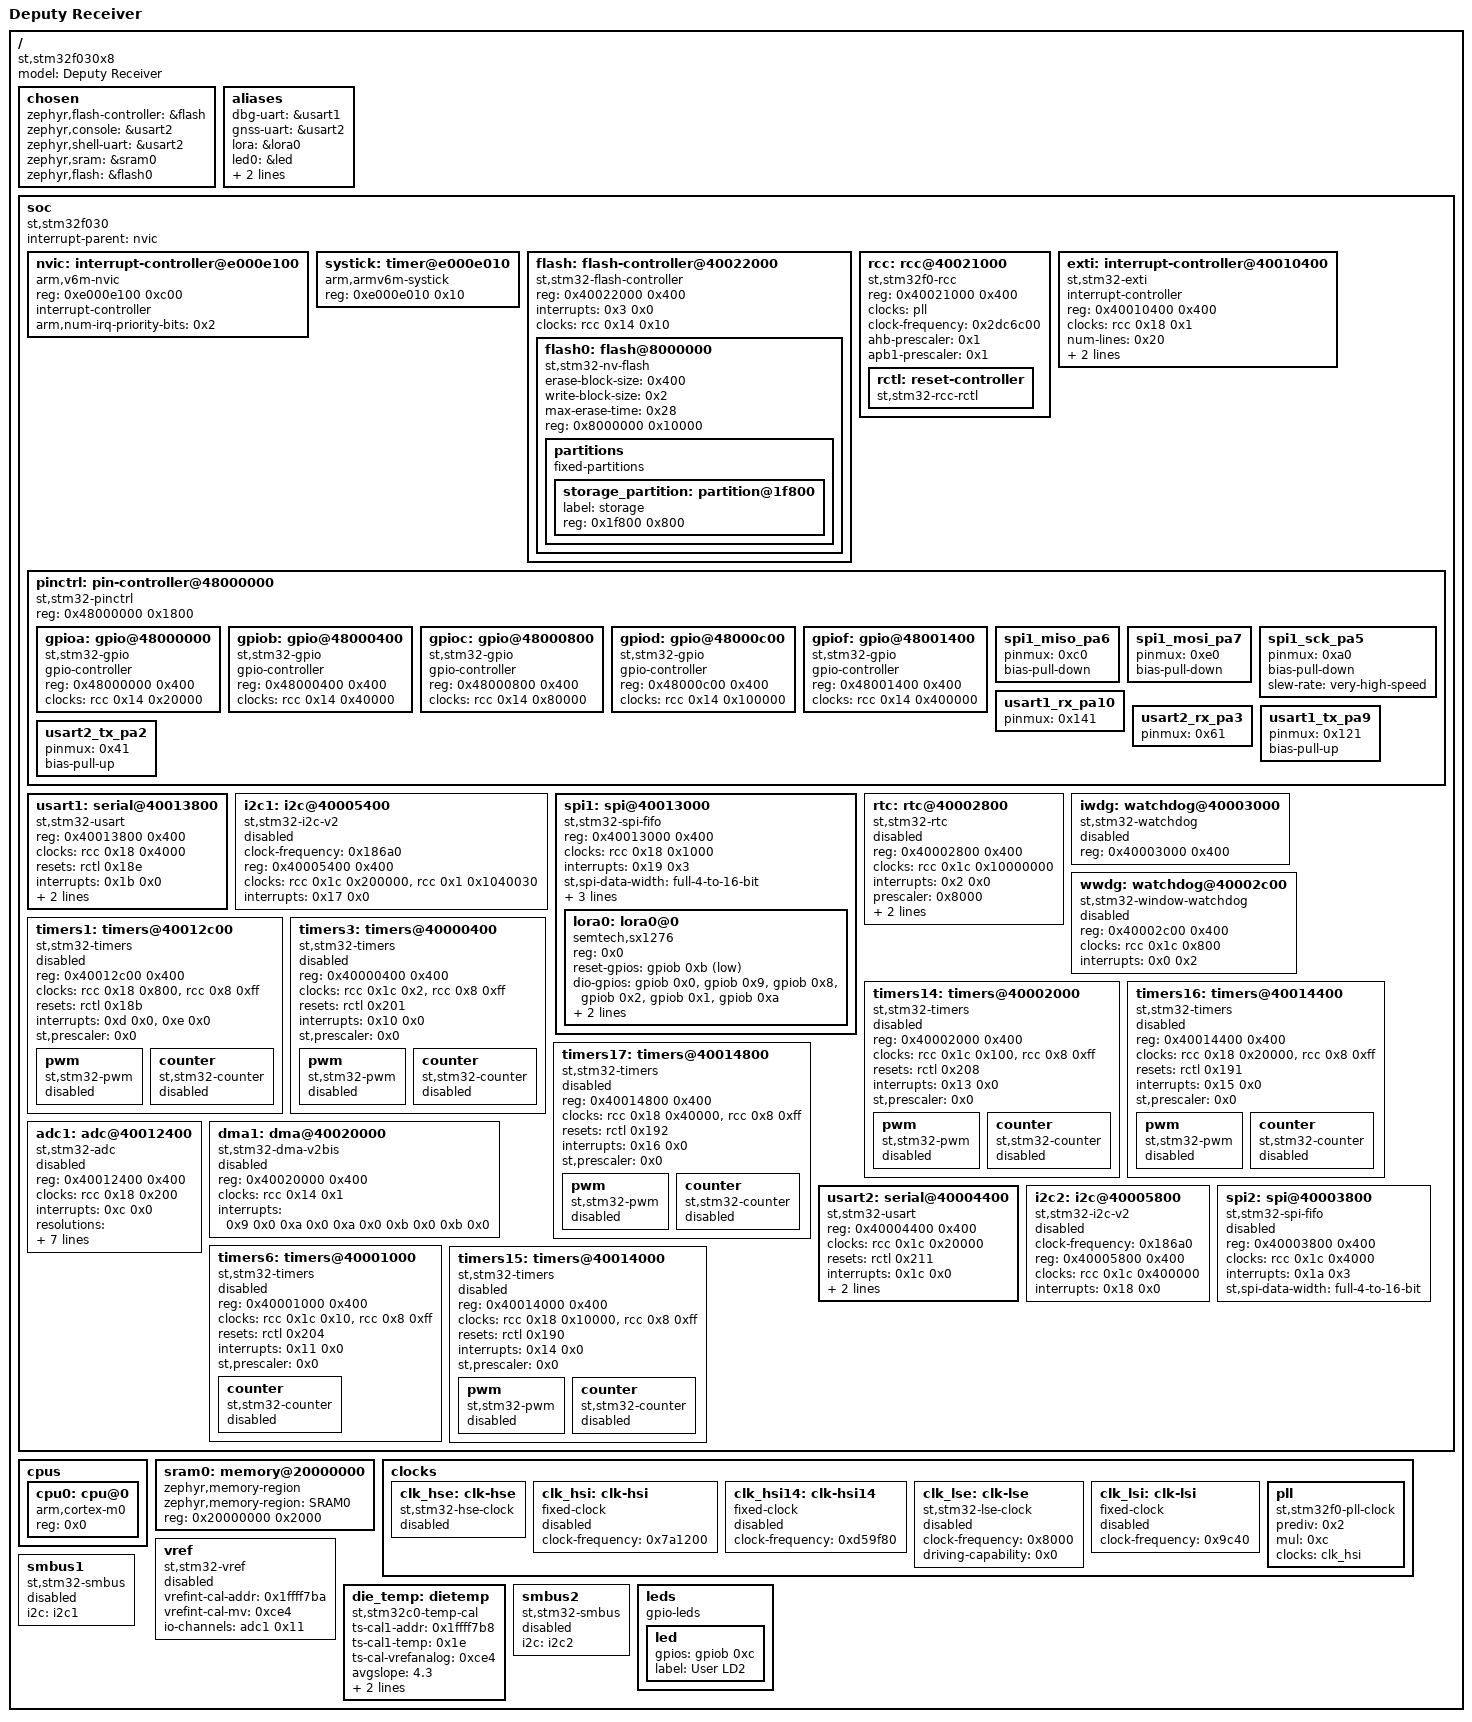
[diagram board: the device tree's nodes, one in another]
/dts-v1/;

/* node '/' defined in zephyr/dts/common/skeleton.dtsi:9 */
/ {
	#address-cells = < 0x1 >;      /* in zephyr/dts/common/skeleton.dtsi:10 */
	#size-cells = < 0x1 >;         /* in zephyr/dts/common/skeleton.dtsi:11 */
	model = "Deputy Receiver";     /* in Outlaw-GPS-Tracker-Firmware/boards/deputy/deputy.dts:13 */
	compatible = "st,stm32f030x8"; /* in Outlaw-GPS-Tracker-Firmware/boards/deputy/deputy.dts:14 */

	/* node '/chosen' defined in zephyr/dts/common/skeleton.dtsi:13 */
	chosen {
		zephyr,flash-controller = &flash; /* in zephyr/dts/arm/st/f0/stm32f0.dtsi:24 */
		zephyr,console = &usart2;         /* in Outlaw-GPS-Tracker-Firmware/boards/deputy/deputy.dts:17 */
		zephyr,shell-uart = &usart2;      /* in Outlaw-GPS-Tracker-Firmware/boards/deputy/deputy.dts:18 */
		zephyr,sram = &sram0;             /* in Outlaw-GPS-Tracker-Firmware/boards/deputy/deputy.dts:19 */
		zephyr,flash = &flash0;           /* in Outlaw-GPS-Tracker-Firmware/boards/deputy/deputy.dts:20 */
	};

	/* node '/aliases' defined in zephyr/dts/common/skeleton.dtsi:15 */
	aliases {
		dbg-uart = &usart1;    /* in Outlaw-GPS-Tracker-Firmware/boards/deputy/deputy.dts:32 */
		gnss-uart = &usart2;   /* in Outlaw-GPS-Tracker-Firmware/boards/deputy/deputy.dts:33 */
		lora = &lora0;         /* in Outlaw-GPS-Tracker-Firmware/boards/deputy/deputy.dts:34 */
		led0 = &led;           /* in Outlaw-GPS-Tracker-Firmware/boards/deputy/deputy.dts:35 */
		watchdog0 = &iwdg;     /* in Outlaw-GPS-Tracker-Firmware/boards/deputy/deputy.dts:36 */
		die-temp0 = &die_temp; /* in Outlaw-GPS-Tracker-Firmware/boards/deputy/deputy.dts:37 */
	};

	/* node '/soc' defined in zephyr/dts/arm/armv6-m.dtsi:6 */
	soc {
		#address-cells = < 0x1 >;     /* in zephyr/dts/arm/armv6-m.dtsi:7 */
		#size-cells = < 0x1 >;        /* in zephyr/dts/arm/armv6-m.dtsi:8 */
		interrupt-parent = < &nvic >; /* in zephyr/dts/arm/armv6-m.dtsi:10 */
		ranges;                       /* in zephyr/dts/arm/armv6-m.dtsi:11 */
		compatible = "st,stm32f030",
		             "st,stm32f0",
		             "simple-bus";    /* in zephyr/dts/arm/st/f0/stm32f030.dtsi:11 */

		/* node '/soc/interrupt-controller@e000e100' defined in zephyr/dts/arm/armv6-m.dtsi:13 */
		nvic: interrupt-controller@e000e100 {
			#address-cells = < 0x1 >;            /* in zephyr/dts/arm/armv6-m.dtsi:14 */
			compatible = "arm,v6m-nvic";         /* in zephyr/dts/arm/armv6-m.dtsi:15 */
			reg = < 0xe000e100 0xc00 >;          /* in zephyr/dts/arm/armv6-m.dtsi:16 */
			interrupt-controller;                /* in zephyr/dts/arm/armv6-m.dtsi:17 */
			#interrupt-cells = < 0x2 >;          /* in zephyr/dts/arm/armv6-m.dtsi:18 */
			arm,num-irq-priority-bits = < 0x2 >; /* in zephyr/dts/arm/st/f0/stm32f0.dtsi:399 */
			phandle = < 0x1 >;                   /* in zephyr/dts/arm/armv6-m.dtsi:10 */
		};

		/* node '/soc/timer@e000e010' defined in zephyr/dts/arm/armv6-m.dtsi:21 */
		systick: timer@e000e010 {
			compatible = "arm,armv6m-systick"; /* in zephyr/dts/arm/armv6-m.dtsi:22 */
			reg = < 0xe000e010 0x10 >;         /* in zephyr/dts/arm/armv6-m.dtsi:23 */
		};

		/* node '/soc/flash-controller@40022000' defined in zephyr/dts/arm/st/f0/stm32f0.dtsi:87 */
		flash: flash-controller@40022000 {
			compatible = "st,stm32-flash-controller",
			             "st,stm32f1-flash-controller"; /* in zephyr/dts/arm/st/f0/stm32f0.dtsi:88 */
			reg = < 0x40022000 0x400 >;                 /* in zephyr/dts/arm/st/f0/stm32f0.dtsi:89 */
			interrupts = < 0x3 0x0 >;                   /* in zephyr/dts/arm/st/f0/stm32f0.dtsi:90 */
			clocks = < &rcc 0x14 0x10 >;                /* in zephyr/dts/arm/st/f0/stm32f0.dtsi:91 */
			#address-cells = < 0x1 >;                   /* in zephyr/dts/arm/st/f0/stm32f0.dtsi:93 */
			#size-cells = < 0x1 >;                      /* in zephyr/dts/arm/st/f0/stm32f0.dtsi:94 */

			/* node '/soc/flash-controller@40022000/flash@8000000' defined in zephyr/dts/arm/st/f0/stm32f0.dtsi:96 */
			flash0: flash@8000000 {
				compatible = "st,stm32-nv-flash",
				             "soc-nv-flash";      /* in zephyr/dts/arm/st/f0/stm32f0.dtsi:97 */
				erase-block-size = < 0x400 >;     /* in zephyr/dts/arm/st/f0/stm32f0.dtsi:98 */
				write-block-size = < 0x2 >;       /* in zephyr/dts/arm/st/f0/stm32f0.dtsi:99 */
				max-erase-time = < 0x28 >;        /* in zephyr/dts/arm/st/f0/stm32f0.dtsi:101 */
				reg = < 0x8000000 0x10000 >;      /* in zephyr/dts/arm/st/f0/stm32f030X8.dtsi:16 */

				/* node '/soc/flash-controller@40022000/flash@8000000/partitions' defined in Outlaw-GPS-Tracker-Firmware/boards/deputy/deputy.dts:99 */
				partitions {
					compatible = "fixed-partitions"; /* in Outlaw-GPS-Tracker-Firmware/boards/deputy/deputy.dts:100 */
					#address-cells = < 0x1 >;        /* in Outlaw-GPS-Tracker-Firmware/boards/deputy/deputy.dts:101 */
					#size-cells = < 0x1 >;           /* in Outlaw-GPS-Tracker-Firmware/boards/deputy/deputy.dts:102 */

					/* node '/soc/flash-controller@40022000/flash@8000000/partitions/partition@1f800' defined in Outlaw-GPS-Tracker-Firmware/boards/deputy/deputy.dts:105 */
					storage_partition: partition@1f800 {
						label = "storage";       /* in Outlaw-GPS-Tracker-Firmware/boards/deputy/deputy.dts:106 */
						reg = < 0x1f800 0x800 >; /* in Outlaw-GPS-Tracker-Firmware/boards/deputy/deputy.dts:107 */
					};
				};
			};
		};

		/* node '/soc/rcc@40021000' defined in zephyr/dts/arm/st/f0/stm32f0.dtsi:105 */
		rcc: rcc@40021000 {
			compatible = "st,stm32f0-rcc";   /* in zephyr/dts/arm/st/f0/stm32f0.dtsi:106 */
			#clock-cells = < 0x2 >;          /* in zephyr/dts/arm/st/f0/stm32f0.dtsi:107 */
			reg = < 0x40021000 0x400 >;      /* in zephyr/dts/arm/st/f0/stm32f0.dtsi:108 */
			clocks = < &pll >;               /* in Outlaw-GPS-Tracker-Firmware/boards/deputy/deputy.dts:49 */
			clock-frequency = < 0x2dc6c00 >; /* in Outlaw-GPS-Tracker-Firmware/boards/deputy/deputy.dts:50 */
			ahb-prescaler = < 0x1 >;         /* in Outlaw-GPS-Tracker-Firmware/boards/deputy/deputy.dts:51 */
			apb1-prescaler = < 0x1 >;        /* in Outlaw-GPS-Tracker-Firmware/boards/deputy/deputy.dts:52 */
			phandle = < 0x2 >;               /* in zephyr/dts/arm/st/f0/stm32f0.dtsi:91 */

			/* node '/soc/rcc@40021000/reset-controller' defined in zephyr/dts/arm/st/f0/stm32f0.dtsi:110 */
			rctl: reset-controller {
				compatible = "st,stm32-rcc-rctl"; /* in zephyr/dts/arm/st/f0/stm32f0.dtsi:111 */
				#reset-cells = < 0x1 >;           /* in zephyr/dts/arm/st/f0/stm32f0.dtsi:112 */
				phandle = < 0x4 >;                /* in zephyr/dts/arm/st/f0/stm32f0.dtsi:180 */
			};
		};

		/* node '/soc/interrupt-controller@40010400' defined in zephyr/dts/arm/st/f0/stm32f0.dtsi:116 */
		exti: interrupt-controller@40010400 {
			compatible = "st,stm32-exti"; /* in zephyr/dts/arm/st/f0/stm32f0.dtsi:117 */
			interrupt-controller;         /* in zephyr/dts/arm/st/f0/stm32f0.dtsi:118 */
			#interrupt-cells = < 0x1 >;   /* in zephyr/dts/arm/st/f0/stm32f0.dtsi:119 */
			#address-cells = < 0x0 >;     /* in zephyr/dts/arm/st/f0/stm32f0.dtsi:120 */
			reg = < 0x40010400 0x400 >;   /* in zephyr/dts/arm/st/f0/stm32f0.dtsi:121 */
			clocks = < &rcc 0x18 0x1 >;   /* in zephyr/dts/arm/st/f0/stm32f0.dtsi:122 */
			num-lines = < 0x20 >;         /* in zephyr/dts/arm/st/f0/stm32f0.dtsi:123 */
			interrupts = < 0x5 0x0 >,
			             < 0x6 0x0 >,
			             < 0x7 0x0 >;     /* in zephyr/dts/arm/st/f0/stm32f0.dtsi:124 */
			interrupt-names = "line0-1",
			                  "line2-3",
			                  "line4-15"; /* in zephyr/dts/arm/st/f0/stm32f0.dtsi:125 */
			line-ranges = < 0x0 0x2 >,
			              < 0x2 0x2 >,
			              < 0x4 0xc >;    /* in zephyr/dts/arm/st/f0/stm32f0.dtsi:126 */
		};

		/* node '/soc/pin-controller@48000000' defined in zephyr/dts/arm/st/f0/stm32f0.dtsi:129 */
		pinctrl: pin-controller@48000000 {
			compatible = "st,stm32-pinctrl"; /* in zephyr/dts/arm/st/f0/stm32f0.dtsi:130 */
			#address-cells = < 0x1 >;        /* in zephyr/dts/arm/st/f0/stm32f0.dtsi:131 */
			#size-cells = < 0x1 >;           /* in zephyr/dts/arm/st/f0/stm32f0.dtsi:132 */
			reg = < 0x48000000 0x1800 >;     /* in zephyr/dts/arm/st/f0/stm32f0.dtsi:133 */

			/* node '/soc/pin-controller@48000000/gpio@48000000' defined in zephyr/dts/arm/st/f0/stm32f0.dtsi:135 */
			gpioa: gpio@48000000 {
				compatible = "st,stm32-gpio";   /* in zephyr/dts/arm/st/f0/stm32f0.dtsi:136 */
				gpio-controller;                /* in zephyr/dts/arm/st/f0/stm32f0.dtsi:137 */
				#gpio-cells = < 0x2 >;          /* in zephyr/dts/arm/st/f0/stm32f0.dtsi:138 */
				reg = < 0x48000000 0x400 >;     /* in zephyr/dts/arm/st/f0/stm32f0.dtsi:139 */
				clocks = < &rcc 0x14 0x20000 >; /* in zephyr/dts/arm/st/f0/stm32f0.dtsi:140 */
				phandle = < 0xa >;              /* in Outlaw-GPS-Tracker-Firmware/boards/deputy/deputy.dts:75 */
			};

			/* node '/soc/pin-controller@48000000/gpio@48000400' defined in zephyr/dts/arm/st/f0/stm32f0.dtsi:143 */
			gpiob: gpio@48000400 {
				compatible = "st,stm32-gpio";   /* in zephyr/dts/arm/st/f0/stm32f0.dtsi:144 */
				gpio-controller;                /* in zephyr/dts/arm/st/f0/stm32f0.dtsi:145 */
				#gpio-cells = < 0x2 >;          /* in zephyr/dts/arm/st/f0/stm32f0.dtsi:146 */
				reg = < 0x48000400 0x400 >;     /* in zephyr/dts/arm/st/f0/stm32f0.dtsi:147 */
				clocks = < &rcc 0x14 0x40000 >; /* in zephyr/dts/arm/st/f0/stm32f0.dtsi:148 */
				phandle = < 0xb >;              /* in Outlaw-GPS-Tracker-Firmware/boards/deputy/deputy.dts:81 */
			};

			/* node '/soc/pin-controller@48000000/gpio@48000800' defined in zephyr/dts/arm/st/f0/stm32f0.dtsi:151 */
			gpioc: gpio@48000800 {
				compatible = "st,stm32-gpio";   /* in zephyr/dts/arm/st/f0/stm32f0.dtsi:152 */
				gpio-controller;                /* in zephyr/dts/arm/st/f0/stm32f0.dtsi:153 */
				#gpio-cells = < 0x2 >;          /* in zephyr/dts/arm/st/f0/stm32f0.dtsi:154 */
				reg = < 0x48000800 0x400 >;     /* in zephyr/dts/arm/st/f0/stm32f0.dtsi:155 */
				clocks = < &rcc 0x14 0x80000 >; /* in zephyr/dts/arm/st/f0/stm32f0.dtsi:156 */
			};

			/* node '/soc/pin-controller@48000000/gpio@48000c00' defined in zephyr/dts/arm/st/f0/stm32f0.dtsi:159 */
			gpiod: gpio@48000c00 {
				compatible = "st,stm32-gpio";    /* in zephyr/dts/arm/st/f0/stm32f0.dtsi:160 */
				gpio-controller;                 /* in zephyr/dts/arm/st/f0/stm32f0.dtsi:161 */
				#gpio-cells = < 0x2 >;           /* in zephyr/dts/arm/st/f0/stm32f0.dtsi:162 */
				reg = < 0x48000c00 0x400 >;      /* in zephyr/dts/arm/st/f0/stm32f0.dtsi:163 */
				clocks = < &rcc 0x14 0x100000 >; /* in zephyr/dts/arm/st/f0/stm32f0.dtsi:164 */
			};

			/* node '/soc/pin-controller@48000000/gpio@48001400' defined in zephyr/dts/arm/st/f0/stm32f0.dtsi:167 */
			gpiof: gpio@48001400 {
				compatible = "st,stm32-gpio";    /* in zephyr/dts/arm/st/f0/stm32f0.dtsi:168 */
				gpio-controller;                 /* in zephyr/dts/arm/st/f0/stm32f0.dtsi:169 */
				#gpio-cells = < 0x2 >;           /* in zephyr/dts/arm/st/f0/stm32f0.dtsi:170 */
				reg = < 0x48001400 0x400 >;      /* in zephyr/dts/arm/st/f0/stm32f0.dtsi:171 */
				clocks = < &rcc 0x14 0x400000 >; /* in zephyr/dts/arm/st/f0/stm32f0.dtsi:172 */
			};

			/* node '/soc/pin-controller@48000000/spi1_miso_pa6' defined in modules/hal/stm32/dts/st/f0/stm32f030c8tx-pinctrl.dtsi:291 */
			spi1_miso_pa6: spi1_miso_pa6 {
				pinmux = < 0xc0 >; /* in modules/hal/stm32/dts/st/f0/stm32f030c8tx-pinctrl.dtsi:292 */
				bias-pull-down;    /* in modules/hal/stm32/dts/st/f0/stm32f030c8tx-pinctrl.dtsi:293 */
				phandle = < 0x8 >; /* in Outlaw-GPS-Tracker-Firmware/boards/deputy/deputy.dts:73 */
			};

			/* node '/soc/pin-controller@48000000/spi1_mosi_pa7' defined in modules/hal/stm32/dts/st/f0/stm32f030c8tx-pinctrl.dtsi:308 */
			spi1_mosi_pa7: spi1_mosi_pa7 {
				pinmux = < 0xe0 >; /* in modules/hal/stm32/dts/st/f0/stm32f030c8tx-pinctrl.dtsi:309 */
				bias-pull-down;    /* in modules/hal/stm32/dts/st/f0/stm32f030c8tx-pinctrl.dtsi:310 */
				phandle = < 0x9 >; /* in Outlaw-GPS-Tracker-Firmware/boards/deputy/deputy.dts:73 */
			};

			/* node '/soc/pin-controller@48000000/spi1_sck_pa5' defined in modules/hal/stm32/dts/st/f0/stm32f030c8tx-pinctrl.dtsi:342 */
			spi1_sck_pa5: spi1_sck_pa5 {
				pinmux = < 0xa0 >;             /* in modules/hal/stm32/dts/st/f0/stm32f030c8tx-pinctrl.dtsi:343 */
				bias-pull-down;                /* in modules/hal/stm32/dts/st/f0/stm32f030c8tx-pinctrl.dtsi:344 */
				slew-rate = "very-high-speed"; /* in modules/hal/stm32/dts/st/f0/stm32f030c8tx-pinctrl.dtsi:345 */
				phandle = < 0x7 >;             /* in Outlaw-GPS-Tracker-Firmware/boards/deputy/deputy.dts:73 */
			};

			/* node '/soc/pin-controller@48000000/usart1_rx_pa10' defined in modules/hal/stm32/dts/st/f0/stm32f030c8tx-pinctrl.dtsi:542 */
			usart1_rx_pa10: usart1_rx_pa10 {
				pinmux = < 0x141 >; /* in modules/hal/stm32/dts/st/f0/stm32f030c8tx-pinctrl.dtsi:543 */
				phandle = < 0x6 >;  /* in Outlaw-GPS-Tracker-Firmware/boards/deputy/deputy.dts:58 */
			};

			/* node '/soc/pin-controller@48000000/usart2_rx_pa3' defined in modules/hal/stm32/dts/st/f0/stm32f030c8tx-pinctrl.dtsi:550 */
			usart2_rx_pa3: usart2_rx_pa3 {
				pinmux = < 0x61 >; /* in modules/hal/stm32/dts/st/f0/stm32f030c8tx-pinctrl.dtsi:551 */
				phandle = < 0xd >; /* in Outlaw-GPS-Tracker-Firmware/boards/deputy/deputy.dts:66 */
			};

			/* node '/soc/pin-controller@48000000/usart1_tx_pa9' defined in modules/hal/stm32/dts/st/f0/stm32f030c8tx-pinctrl.dtsi:560 */
			usart1_tx_pa9: usart1_tx_pa9 {
				pinmux = < 0x121 >; /* in modules/hal/stm32/dts/st/f0/stm32f030c8tx-pinctrl.dtsi:561 */
				bias-pull-up;       /* in modules/hal/stm32/dts/st/f0/stm32f030c8tx-pinctrl.dtsi:562 */
				phandle = < 0x5 >;  /* in Outlaw-GPS-Tracker-Firmware/boards/deputy/deputy.dts:58 */
			};

			/* node '/soc/pin-controller@48000000/usart2_tx_pa2' defined in modules/hal/stm32/dts/st/f0/stm32f030c8tx-pinctrl.dtsi:570 */
			usart2_tx_pa2: usart2_tx_pa2 {
				pinmux = < 0x41 >; /* in modules/hal/stm32/dts/st/f0/stm32f030c8tx-pinctrl.dtsi:571 */
				bias-pull-up;      /* in modules/hal/stm32/dts/st/f0/stm32f030c8tx-pinctrl.dtsi:572 */
				phandle = < 0xc >; /* in Outlaw-GPS-Tracker-Firmware/boards/deputy/deputy.dts:66 */
			};
		};

		/* node '/soc/serial@40013800' defined in zephyr/dts/arm/st/f0/stm32f0.dtsi:176 */
		usart1: serial@40013800 {
			compatible = "st,stm32-usart",
			             "st,stm32-uart";                   /* in zephyr/dts/arm/st/f0/stm32f0.dtsi:177 */
			reg = < 0x40013800 0x400 >;                     /* in zephyr/dts/arm/st/f0/stm32f0.dtsi:178 */
			clocks = < &rcc 0x18 0x4000 >;                  /* in zephyr/dts/arm/st/f0/stm32f0.dtsi:179 */
			resets = < &rctl 0x18e >;                       /* in zephyr/dts/arm/st/f0/stm32f0.dtsi:180 */
			interrupts = < 0x1b 0x0 >;                      /* in zephyr/dts/arm/st/f0/stm32f0.dtsi:181 */
			pinctrl-0 = < &usart1_tx_pa9 &usart1_rx_pa10 >; /* in Outlaw-GPS-Tracker-Firmware/boards/deputy/deputy.dts:58 */
			pinctrl-names = "default";                      /* in Outlaw-GPS-Tracker-Firmware/boards/deputy/deputy.dts:59 */
			current-speed = < 0x2580 >;                     /* in Outlaw-GPS-Tracker-Firmware/boards/deputy/deputy.dts:60 */
			status = "okay";                                /* in Outlaw-GPS-Tracker-Firmware/boards/deputy/deputy.dts:61 */
		};

		/* node '/soc/i2c@40005400' defined in zephyr/dts/arm/st/f0/stm32f0.dtsi:185 */
		i2c1: i2c@40005400 {
			compatible = "st,stm32-i2c-v2";  /* in zephyr/dts/arm/st/f0/stm32f0.dtsi:186 */
			clock-frequency = < 0x186a0 >;   /* in zephyr/dts/arm/st/f0/stm32f0.dtsi:187 */
			#address-cells = < 0x1 >;        /* in zephyr/dts/arm/st/f0/stm32f0.dtsi:188 */
			#size-cells = < 0x0 >;           /* in zephyr/dts/arm/st/f0/stm32f0.dtsi:189 */
			reg = < 0x40005400 0x400 >;      /* in zephyr/dts/arm/st/f0/stm32f0.dtsi:190 */
			clocks = < &rcc 0x1c 0x200000 >,
			         < &rcc 0x1 0x1040030 >; /* in zephyr/dts/arm/st/f0/stm32f0.dtsi:191 */
			interrupts = < 0x17 0x0 >;       /* in zephyr/dts/arm/st/f0/stm32f0.dtsi:196 */
			interrupt-names = "combined";    /* in zephyr/dts/arm/st/f0/stm32f0.dtsi:197 */
			status = "disabled";             /* in zephyr/dts/arm/st/f0/stm32f0.dtsi:198 */
			phandle = < 0x10 >;              /* in zephyr/dts/arm/st/f0/stm32f0.dtsi:393 */
		};

		/* node '/soc/spi@40013000' defined in zephyr/dts/arm/st/f0/stm32f0.dtsi:201 */
		spi1: spi@40013000 {
			compatible = "st,stm32-spi-fifo",
			             "st,stm32-spi";                                 /* in zephyr/dts/arm/st/f0/stm32f0.dtsi:202 */
			#address-cells = < 0x1 >;                                    /* in zephyr/dts/arm/st/f0/stm32f0.dtsi:203 */
			#size-cells = < 0x0 >;                                       /* in zephyr/dts/arm/st/f0/stm32f0.dtsi:204 */
			reg = < 0x40013000 0x400 >;                                  /* in zephyr/dts/arm/st/f0/stm32f0.dtsi:205 */
			clocks = < &rcc 0x18 0x1000 >;                               /* in zephyr/dts/arm/st/f0/stm32f0.dtsi:206 */
			interrupts = < 0x19 0x3 >;                                   /* in zephyr/dts/arm/st/f0/stm32f0.dtsi:207 */
			st,spi-data-width = "full-4-to-16-bit";                      /* in zephyr/dts/arm/st/f0/stm32f0.dtsi:208 */
			pinctrl-0 = < &spi1_sck_pa5 &spi1_miso_pa6 &spi1_mosi_pa7 >; /* in Outlaw-GPS-Tracker-Firmware/boards/deputy/deputy.dts:73 */
			pinctrl-names = "default";                                   /* in Outlaw-GPS-Tracker-Firmware/boards/deputy/deputy.dts:74 */
			cs-gpios = < &gpioa 0x4 0x11 >;                              /* in Outlaw-GPS-Tracker-Firmware/boards/deputy/deputy.dts:75 */
			status = "okay";                                             /* in Outlaw-GPS-Tracker-Firmware/boards/deputy/deputy.dts:76 */

			/* node '/soc/spi@40013000/lora0@0' defined in Outlaw-GPS-Tracker-Firmware/boards/deputy/deputy.dts:78 */
			lora0: lora0@0 {
				compatible = "semtech,sx1276";       /* in Outlaw-GPS-Tracker-Firmware/boards/deputy/deputy.dts:79 */
				reg = < 0x0 >;                       /* in Outlaw-GPS-Tracker-Firmware/boards/deputy/deputy.dts:80 */
				reset-gpios = < &gpiob 0xb 0x1 >;    /* in Outlaw-GPS-Tracker-Firmware/boards/deputy/deputy.dts:81 */
				dio-gpios = < &gpiob 0x0 0x20 >,
				            < &gpiob 0x9 0x20 >,
				            < &gpiob 0x8 0x20 >,
				            < &gpiob 0x2 0x20 >,
				            < &gpiob 0x1 0x20 >,
				            < &gpiob 0xa 0x20 >;     /* in Outlaw-GPS-Tracker-Firmware/boards/deputy/deputy.dts:82 */
				power-amplifier-output = "pa-boost"; /* in Outlaw-GPS-Tracker-Firmware/boards/deputy/deputy.dts:88 */
				spi-max-frequency = < 0x989680 >;    /* in Outlaw-GPS-Tracker-Firmware/boards/deputy/deputy.dts:89 */
				status = "okay";                     /* in Outlaw-GPS-Tracker-Firmware/boards/deputy/deputy.dts:90 */
			};
		};

		/* node '/soc/rtc@40002800' defined in zephyr/dts/arm/st/f0/stm32f0.dtsi:212 */
		rtc: rtc@40002800 {
			compatible = "st,stm32-rtc";       /* in zephyr/dts/arm/st/f0/stm32f0.dtsi:213 */
			reg = < 0x40002800 0x400 >;        /* in zephyr/dts/arm/st/f0/stm32f0.dtsi:214 */
			clocks = < &rcc 0x1c 0x10000000 >; /* in zephyr/dts/arm/st/f0/stm32f0.dtsi:215 */
			interrupts = < 0x2 0x0 >;          /* in zephyr/dts/arm/st/f0/stm32f0.dtsi:216 */
			prescaler = < 0x8000 >;            /* in zephyr/dts/arm/st/f0/stm32f0.dtsi:217 */
			alarms-count = < 0x1 >;            /* in zephyr/dts/arm/st/f0/stm32f0.dtsi:218 */
			alrm-exti-line = < 0x11 >;         /* in zephyr/dts/arm/st/f0/stm32f0.dtsi:219 */
			status = "disabled";               /* in zephyr/dts/arm/st/f0/stm32f0.dtsi:220 */
		};

		/* node '/soc/watchdog@40003000' defined in zephyr/dts/arm/st/f0/stm32f0.dtsi:223 */
		iwdg: watchdog@40003000 {
			compatible = "st,stm32-watchdog"; /* in zephyr/dts/arm/st/f0/stm32f0.dtsi:224 */
			reg = < 0x40003000 0x400 >;       /* in zephyr/dts/arm/st/f0/stm32f0.dtsi:225 */
			status = "disabled";              /* in zephyr/dts/arm/st/f0/stm32f0.dtsi:226 */
		};

		/* node '/soc/watchdog@40002c00' defined in zephyr/dts/arm/st/f0/stm32f0.dtsi:229 */
		wwdg: watchdog@40002c00 {
			compatible = "st,stm32-window-watchdog"; /* in zephyr/dts/arm/st/f0/stm32f0.dtsi:230 */
			reg = < 0x40002c00 0x400 >;              /* in zephyr/dts/arm/st/f0/stm32f0.dtsi:231 */
			clocks = < &rcc 0x1c 0x800 >;            /* in zephyr/dts/arm/st/f0/stm32f0.dtsi:232 */
			interrupts = < 0x0 0x2 >;                /* in zephyr/dts/arm/st/f0/stm32f0.dtsi:233 */
			status = "disabled";                     /* in zephyr/dts/arm/st/f0/stm32f0.dtsi:234 */
		};

		/* node '/soc/timers@40012c00' defined in zephyr/dts/arm/st/f0/stm32f0.dtsi:237 */
		timers1: timers@40012c00 {
			compatible = "st,stm32-timers";     /* in zephyr/dts/arm/st/f0/stm32f0.dtsi:238 */
			reg = < 0x40012c00 0x400 >;         /* in zephyr/dts/arm/st/f0/stm32f0.dtsi:239 */
			clocks = < &rcc 0x18 0x800 >,
			         < &rcc 0x8 0xff >;         /* in zephyr/dts/arm/st/f0/stm32f0.dtsi:240 */
			resets = < &rctl 0x18b >;           /* in zephyr/dts/arm/st/f0/stm32f0.dtsi:242 */
			interrupts = < 0xd 0x0 >,
			             < 0xe 0x0 >;           /* in zephyr/dts/arm/st/f0/stm32f0.dtsi:243 */
			interrupt-names = "brk_up_trg_com",
			                  "cc";             /* in zephyr/dts/arm/st/f0/stm32f0.dtsi:244 */
			st,prescaler = < 0x0 >;             /* in zephyr/dts/arm/st/f0/stm32f0.dtsi:245 */
			status = "disabled";                /* in zephyr/dts/arm/st/f0/stm32f0.dtsi:246 */

			/* node '/soc/timers@40012c00/pwm' defined in zephyr/dts/arm/st/f0/stm32f0.dtsi:248 */
			pwm {
				compatible = "st,stm32-pwm"; /* in zephyr/dts/arm/st/f0/stm32f0.dtsi:249 */
				status = "disabled";         /* in zephyr/dts/arm/st/f0/stm32f0.dtsi:250 */
				#pwm-cells = < 0x3 >;        /* in zephyr/dts/arm/st/f0/stm32f0.dtsi:251 */
			};

			/* node '/soc/timers@40012c00/counter' defined in zephyr/dts/arm/st/f0/stm32f0.dtsi:254 */
			counter {
				compatible = "st,stm32-counter"; /* in zephyr/dts/arm/st/f0/stm32f0.dtsi:255 */
				status = "disabled";             /* in zephyr/dts/arm/st/f0/stm32f0.dtsi:256 */
			};
		};

		/* node '/soc/timers@40000400' defined in zephyr/dts/arm/st/f0/stm32f0.dtsi:260 */
		timers3: timers@40000400 {
			compatible = "st,stm32-timers"; /* in zephyr/dts/arm/st/f0/stm32f0.dtsi:261 */
			reg = < 0x40000400 0x400 >;     /* in zephyr/dts/arm/st/f0/stm32f0.dtsi:262 */
			clocks = < &rcc 0x1c 0x2 >,
			         < &rcc 0x8 0xff >;     /* in zephyr/dts/arm/st/f0/stm32f0.dtsi:263 */
			resets = < &rctl 0x201 >;       /* in zephyr/dts/arm/st/f0/stm32f0.dtsi:265 */
			interrupts = < 0x10 0x0 >;      /* in zephyr/dts/arm/st/f0/stm32f0.dtsi:266 */
			interrupt-names = "global";     /* in zephyr/dts/arm/st/f0/stm32f0.dtsi:267 */
			st,prescaler = < 0x0 >;         /* in zephyr/dts/arm/st/f0/stm32f0.dtsi:268 */
			status = "disabled";            /* in zephyr/dts/arm/st/f0/stm32f0.dtsi:269 */

			/* node '/soc/timers@40000400/pwm' defined in zephyr/dts/arm/st/f0/stm32f0.dtsi:271 */
			pwm {
				compatible = "st,stm32-pwm"; /* in zephyr/dts/arm/st/f0/stm32f0.dtsi:272 */
				status = "disabled";         /* in zephyr/dts/arm/st/f0/stm32f0.dtsi:273 */
				#pwm-cells = < 0x3 >;        /* in zephyr/dts/arm/st/f0/stm32f0.dtsi:274 */
			};

			/* node '/soc/timers@40000400/counter' defined in zephyr/dts/arm/st/f0/stm32f0.dtsi:277 */
			counter {
				compatible = "st,stm32-counter"; /* in zephyr/dts/arm/st/f0/stm32f0.dtsi:278 */
				status = "disabled";             /* in zephyr/dts/arm/st/f0/stm32f0.dtsi:279 */
			};
		};

		/* node '/soc/timers@40002000' defined in zephyr/dts/arm/st/f0/stm32f0.dtsi:283 */
		timers14: timers@40002000 {
			compatible = "st,stm32-timers"; /* in zephyr/dts/arm/st/f0/stm32f0.dtsi:284 */
			reg = < 0x40002000 0x400 >;     /* in zephyr/dts/arm/st/f0/stm32f0.dtsi:285 */
			clocks = < &rcc 0x1c 0x100 >,
			         < &rcc 0x8 0xff >;     /* in zephyr/dts/arm/st/f0/stm32f0.dtsi:286 */
			resets = < &rctl 0x208 >;       /* in zephyr/dts/arm/st/f0/stm32f0.dtsi:288 */
			interrupts = < 0x13 0x0 >;      /* in zephyr/dts/arm/st/f0/stm32f0.dtsi:289 */
			interrupt-names = "global";     /* in zephyr/dts/arm/st/f0/stm32f0.dtsi:290 */
			st,prescaler = < 0x0 >;         /* in zephyr/dts/arm/st/f0/stm32f0.dtsi:291 */
			status = "disabled";            /* in zephyr/dts/arm/st/f0/stm32f0.dtsi:292 */

			/* node '/soc/timers@40002000/pwm' defined in zephyr/dts/arm/st/f0/stm32f0.dtsi:294 */
			pwm {
				compatible = "st,stm32-pwm"; /* in zephyr/dts/arm/st/f0/stm32f0.dtsi:295 */
				status = "disabled";         /* in zephyr/dts/arm/st/f0/stm32f0.dtsi:296 */
				#pwm-cells = < 0x3 >;        /* in zephyr/dts/arm/st/f0/stm32f0.dtsi:297 */
			};

			/* node '/soc/timers@40002000/counter' defined in zephyr/dts/arm/st/f0/stm32f0.dtsi:300 */
			counter {
				compatible = "st,stm32-counter"; /* in zephyr/dts/arm/st/f0/stm32f0.dtsi:301 */
				status = "disabled";             /* in zephyr/dts/arm/st/f0/stm32f0.dtsi:302 */
			};
		};

		/* node '/soc/timers@40014400' defined in zephyr/dts/arm/st/f0/stm32f0.dtsi:306 */
		timers16: timers@40014400 {
			compatible = "st,stm32-timers"; /* in zephyr/dts/arm/st/f0/stm32f0.dtsi:307 */
			reg = < 0x40014400 0x400 >;     /* in zephyr/dts/arm/st/f0/stm32f0.dtsi:308 */
			clocks = < &rcc 0x18 0x20000 >,
			         < &rcc 0x8 0xff >;     /* in zephyr/dts/arm/st/f0/stm32f0.dtsi:309 */
			resets = < &rctl 0x191 >;       /* in zephyr/dts/arm/st/f0/stm32f0.dtsi:311 */
			interrupts = < 0x15 0x0 >;      /* in zephyr/dts/arm/st/f0/stm32f0.dtsi:312 */
			interrupt-names = "global";     /* in zephyr/dts/arm/st/f0/stm32f0.dtsi:313 */
			st,prescaler = < 0x0 >;         /* in zephyr/dts/arm/st/f0/stm32f0.dtsi:314 */
			status = "disabled";            /* in zephyr/dts/arm/st/f0/stm32f0.dtsi:315 */

			/* node '/soc/timers@40014400/pwm' defined in zephyr/dts/arm/st/f0/stm32f0.dtsi:317 */
			pwm {
				compatible = "st,stm32-pwm"; /* in zephyr/dts/arm/st/f0/stm32f0.dtsi:318 */
				status = "disabled";         /* in zephyr/dts/arm/st/f0/stm32f0.dtsi:319 */
				#pwm-cells = < 0x3 >;        /* in zephyr/dts/arm/st/f0/stm32f0.dtsi:320 */
			};

			/* node '/soc/timers@40014400/counter' defined in zephyr/dts/arm/st/f0/stm32f0.dtsi:323 */
			counter {
				compatible = "st,stm32-counter"; /* in zephyr/dts/arm/st/f0/stm32f0.dtsi:324 */
				status = "disabled";             /* in zephyr/dts/arm/st/f0/stm32f0.dtsi:325 */
			};
		};

		/* node '/soc/timers@40014800' defined in zephyr/dts/arm/st/f0/stm32f0.dtsi:329 */
		timers17: timers@40014800 {
			compatible = "st,stm32-timers"; /* in zephyr/dts/arm/st/f0/stm32f0.dtsi:330 */
			reg = < 0x40014800 0x400 >;     /* in zephyr/dts/arm/st/f0/stm32f0.dtsi:331 */
			clocks = < &rcc 0x18 0x40000 >,
			         < &rcc 0x8 0xff >;     /* in zephyr/dts/arm/st/f0/stm32f0.dtsi:332 */
			resets = < &rctl 0x192 >;       /* in zephyr/dts/arm/st/f0/stm32f0.dtsi:334 */
			interrupts = < 0x16 0x0 >;      /* in zephyr/dts/arm/st/f0/stm32f0.dtsi:335 */
			interrupt-names = "global";     /* in zephyr/dts/arm/st/f0/stm32f0.dtsi:336 */
			st,prescaler = < 0x0 >;         /* in zephyr/dts/arm/st/f0/stm32f0.dtsi:337 */
			status = "disabled";            /* in zephyr/dts/arm/st/f0/stm32f0.dtsi:338 */

			/* node '/soc/timers@40014800/pwm' defined in zephyr/dts/arm/st/f0/stm32f0.dtsi:340 */
			pwm {
				compatible = "st,stm32-pwm"; /* in zephyr/dts/arm/st/f0/stm32f0.dtsi:341 */
				status = "disabled";         /* in zephyr/dts/arm/st/f0/stm32f0.dtsi:342 */
				#pwm-cells = < 0x3 >;        /* in zephyr/dts/arm/st/f0/stm32f0.dtsi:343 */
			};

			/* node '/soc/timers@40014800/counter' defined in zephyr/dts/arm/st/f0/stm32f0.dtsi:346 */
			counter {
				compatible = "st,stm32-counter"; /* in zephyr/dts/arm/st/f0/stm32f0.dtsi:347 */
				status = "disabled";             /* in zephyr/dts/arm/st/f0/stm32f0.dtsi:348 */
			};
		};

		/* node '/soc/adc@40012400' defined in zephyr/dts/arm/st/f0/stm32f0.dtsi:352 */
		adc1: adc@40012400 {
			compatible = "st,stm32-adc";                               /* in zephyr/dts/arm/st/f0/stm32f0.dtsi:353 */
			reg = < 0x40012400 0x400 >;                                /* in zephyr/dts/arm/st/f0/stm32f0.dtsi:354 */
			clocks = < &rcc 0x18 0x200 >;                              /* in zephyr/dts/arm/st/f0/stm32f0.dtsi:355 */
			clock-names = "adcx";                                      /* in zephyr/dts/arm/st/f0/stm32f0.dtsi:356 */
			interrupts = < 0xc 0x0 >;                                  /* in zephyr/dts/arm/st/f0/stm32f0.dtsi:357 */
			#io-channel-cells = < 0x1 >;                               /* in zephyr/dts/arm/st/f0/stm32f0.dtsi:358 */
			resolutions = < 0x60630c 0x51630c 0x42630c 0x33630c >;     /* in zephyr/dts/arm/st/f0/stm32f0.dtsi:359 */
			sampling-times = < 0x2 0x8 0xe 0x1d 0x2a 0x38 0x48 0xf0 >; /* in zephyr/dts/arm/st/f0/stm32f0.dtsi:363 */
			num-sampling-time-common-channels = < 0x1 >;               /* in zephyr/dts/arm/st/f0/stm32f0.dtsi:364 */
			st,adc-sequencer = "fixed";                                /* in zephyr/dts/arm/st/f0/stm32f0.dtsi:365 */
			st,adc-oversampler = "none";                               /* in zephyr/dts/arm/st/f0/stm32f0.dtsi:366 */
			st,adc-internal-regulator = "none";                        /* in zephyr/dts/arm/st/f0/stm32f0.dtsi:367 */
			status = "disabled";                                       /* in zephyr/dts/arm/st/f0/stm32f0.dtsi:368 */
			phandle = < 0xf >;                                         /* in zephyr/dts/arm/st/f0/stm32f0.dtsi:385 */
		};

		/* node '/soc/dma@40020000' defined in zephyr/dts/arm/st/f0/stm32f0.dtsi:371 */
		dma1: dma@40020000 {
			compatible = "st,stm32-dma-v2bis";                        /* in zephyr/dts/arm/st/f0/stm32f0.dtsi:372 */
			#dma-cells = < 0x2 >;                                     /* in zephyr/dts/arm/st/f0/stm32f0.dtsi:373 */
			reg = < 0x40020000 0x400 >;                               /* in zephyr/dts/arm/st/f0/stm32f0.dtsi:374 */
			clocks = < &rcc 0x14 0x1 >;                               /* in zephyr/dts/arm/st/f0/stm32f0.dtsi:375 */
			interrupts = < 0x9 0x0 0xa 0x0 0xa 0x0 0xb 0x0 0xb 0x0 >; /* in zephyr/dts/arm/st/f0/stm32f0.dtsi:376 */
			status = "disabled";                                      /* in zephyr/dts/arm/st/f0/stm32f0.dtsi:377 */
		};

		/* node '/soc/serial@40004400' defined in zephyr/dts/arm/st/f0/stm32f030X8.dtsi:20 */
		usart2: serial@40004400 {
			compatible = "st,stm32-usart",
			             "st,stm32-uart";                  /* in zephyr/dts/arm/st/f0/stm32f030X8.dtsi:21 */
			reg = < 0x40004400 0x400 >;                    /* in zephyr/dts/arm/st/f0/stm32f030X8.dtsi:22 */
			clocks = < &rcc 0x1c 0x20000 >;                /* in zephyr/dts/arm/st/f0/stm32f030X8.dtsi:23 */
			resets = < &rctl 0x211 >;                      /* in zephyr/dts/arm/st/f0/stm32f030X8.dtsi:24 */
			interrupts = < 0x1c 0x0 >;                     /* in zephyr/dts/arm/st/f0/stm32f030X8.dtsi:25 */
			pinctrl-0 = < &usart2_tx_pa2 &usart2_rx_pa3 >; /* in Outlaw-GPS-Tracker-Firmware/boards/deputy/deputy.dts:66 */
			pinctrl-names = "default";                     /* in Outlaw-GPS-Tracker-Firmware/boards/deputy/deputy.dts:67 */
			current-speed = < 0x2580 >;                    /* in Outlaw-GPS-Tracker-Firmware/boards/deputy/deputy.dts:68 */
			status = "okay";                               /* in Outlaw-GPS-Tracker-Firmware/boards/deputy/deputy.dts:69 */
		};

		/* node '/soc/i2c@40005800' defined in zephyr/dts/arm/st/f0/stm32f030X8.dtsi:29 */
		i2c2: i2c@40005800 {
			compatible = "st,stm32-i2c-v2";  /* in zephyr/dts/arm/st/f0/stm32f030X8.dtsi:30 */
			clock-frequency = < 0x186a0 >;   /* in zephyr/dts/arm/st/f0/stm32f030X8.dtsi:31 */
			#address-cells = < 0x1 >;        /* in zephyr/dts/arm/st/f0/stm32f030X8.dtsi:32 */
			#size-cells = < 0x0 >;           /* in zephyr/dts/arm/st/f0/stm32f030X8.dtsi:33 */
			reg = < 0x40005800 0x400 >;      /* in zephyr/dts/arm/st/f0/stm32f030X8.dtsi:34 */
			clocks = < &rcc 0x1c 0x400000 >; /* in zephyr/dts/arm/st/f0/stm32f030X8.dtsi:35 */
			interrupts = < 0x18 0x0 >;       /* in zephyr/dts/arm/st/f0/stm32f030X8.dtsi:36 */
			interrupt-names = "combined";    /* in zephyr/dts/arm/st/f0/stm32f030X8.dtsi:37 */
			status = "disabled";             /* in zephyr/dts/arm/st/f0/stm32f030X8.dtsi:38 */
			phandle = < 0x11 >;              /* in zephyr/dts/arm/st/f0/stm32f030X8.dtsi:97 */
		};

		/* node '/soc/spi@40003800' defined in zephyr/dts/arm/st/f0/stm32f030X8.dtsi:41 */
		spi2: spi@40003800 {
			compatible = "st,stm32-spi-fifo",
			             "st,stm32-spi";            /* in zephyr/dts/arm/st/f0/stm32f030X8.dtsi:42 */
			#address-cells = < 0x1 >;               /* in zephyr/dts/arm/st/f0/stm32f030X8.dtsi:43 */
			#size-cells = < 0x0 >;                  /* in zephyr/dts/arm/st/f0/stm32f030X8.dtsi:44 */
			reg = < 0x40003800 0x400 >;             /* in zephyr/dts/arm/st/f0/stm32f030X8.dtsi:45 */
			clocks = < &rcc 0x1c 0x4000 >;          /* in zephyr/dts/arm/st/f0/stm32f030X8.dtsi:46 */
			interrupts = < 0x1a 0x3 >;              /* in zephyr/dts/arm/st/f0/stm32f030X8.dtsi:47 */
			st,spi-data-width = "full-4-to-16-bit"; /* in zephyr/dts/arm/st/f0/stm32f030X8.dtsi:48 */
			status = "disabled";                    /* in zephyr/dts/arm/st/f0/stm32f030X8.dtsi:49 */
		};

		/* node '/soc/timers@40001000' defined in zephyr/dts/arm/st/f0/stm32f030X8.dtsi:52 */
		timers6: timers@40001000 {
			compatible = "st,stm32-timers"; /* in zephyr/dts/arm/st/f0/stm32f030X8.dtsi:53 */
			reg = < 0x40001000 0x400 >;     /* in zephyr/dts/arm/st/f0/stm32f030X8.dtsi:54 */
			clocks = < &rcc 0x1c 0x10 >,
			         < &rcc 0x8 0xff >;     /* in zephyr/dts/arm/st/f0/stm32f030X8.dtsi:55 */
			resets = < &rctl 0x204 >;       /* in zephyr/dts/arm/st/f0/stm32f030X8.dtsi:57 */
			interrupts = < 0x11 0x0 >;      /* in zephyr/dts/arm/st/f0/stm32f030X8.dtsi:58 */
			interrupt-names = "global";     /* in zephyr/dts/arm/st/f0/stm32f030X8.dtsi:59 */
			st,prescaler = < 0x0 >;         /* in zephyr/dts/arm/st/f0/stm32f030X8.dtsi:60 */
			status = "disabled";            /* in zephyr/dts/arm/st/f0/stm32f030X8.dtsi:61 */

			/* node '/soc/timers@40001000/counter' defined in zephyr/dts/arm/st/f0/stm32f030X8.dtsi:63 */
			counter {
				compatible = "st,stm32-counter"; /* in zephyr/dts/arm/st/f0/stm32f030X8.dtsi:64 */
				status = "disabled";             /* in zephyr/dts/arm/st/f0/stm32f030X8.dtsi:65 */
			};
		};

		/* node '/soc/timers@40014000' defined in zephyr/dts/arm/st/f0/stm32f030X8.dtsi:69 */
		timers15: timers@40014000 {
			compatible = "st,stm32-timers"; /* in zephyr/dts/arm/st/f0/stm32f030X8.dtsi:70 */
			reg = < 0x40014000 0x400 >;     /* in zephyr/dts/arm/st/f0/stm32f030X8.dtsi:71 */
			clocks = < &rcc 0x18 0x10000 >,
			         < &rcc 0x8 0xff >;     /* in zephyr/dts/arm/st/f0/stm32f030X8.dtsi:72 */
			resets = < &rctl 0x190 >;       /* in zephyr/dts/arm/st/f0/stm32f030X8.dtsi:74 */
			interrupts = < 0x14 0x0 >;      /* in zephyr/dts/arm/st/f0/stm32f030X8.dtsi:75 */
			interrupt-names = "global";     /* in zephyr/dts/arm/st/f0/stm32f030X8.dtsi:76 */
			st,prescaler = < 0x0 >;         /* in zephyr/dts/arm/st/f0/stm32f030X8.dtsi:77 */
			status = "disabled";            /* in zephyr/dts/arm/st/f0/stm32f030X8.dtsi:78 */

			/* node '/soc/timers@40014000/pwm' defined in zephyr/dts/arm/st/f0/stm32f030X8.dtsi:80 */
			pwm {
				compatible = "st,stm32-pwm"; /* in zephyr/dts/arm/st/f0/stm32f030X8.dtsi:81 */
				status = "disabled";         /* in zephyr/dts/arm/st/f0/stm32f030X8.dtsi:82 */
				#pwm-cells = < 0x3 >;        /* in zephyr/dts/arm/st/f0/stm32f030X8.dtsi:83 */
			};

			/* node '/soc/timers@40014000/counter' defined in zephyr/dts/arm/st/f0/stm32f030X8.dtsi:86 */
			counter {
				compatible = "st,stm32-counter"; /* in zephyr/dts/arm/st/f0/stm32f030X8.dtsi:87 */
				status = "disabled";             /* in zephyr/dts/arm/st/f0/stm32f030X8.dtsi:88 */
			};
		};
	};

	/* node '/cpus' defined in zephyr/dts/arm/st/f0/stm32f0.dtsi:27 */
	cpus {
		#address-cells = < 0x1 >; /* in zephyr/dts/arm/st/f0/stm32f0.dtsi:28 */
		#size-cells = < 0x0 >;    /* in zephyr/dts/arm/st/f0/stm32f0.dtsi:29 */

		/* node '/cpus/cpu@0' defined in zephyr/dts/arm/st/f0/stm32f0.dtsi:31 */
		cpu0: cpu@0 {
			device_type = "cpu";          /* in zephyr/dts/arm/st/f0/stm32f0.dtsi:32 */
			compatible = "arm,cortex-m0"; /* in zephyr/dts/arm/st/f0/stm32f0.dtsi:33 */
			reg = < 0x0 >;                /* in zephyr/dts/arm/st/f0/stm32f0.dtsi:34 */
		};
	};

	/* node '/memory@20000000' defined in zephyr/dts/arm/st/f0/stm32f0.dtsi:38 */
	sram0: memory@20000000 {
		compatible = "zephyr,memory-region",
		             "mmio-sram";            /* in zephyr/dts/arm/st/f0/stm32f0.dtsi:39 */
		zephyr,memory-region = "SRAM0";      /* in zephyr/dts/arm/st/f0/stm32f0.dtsi:40 */
		reg = < 0x20000000 0x2000 >;         /* in zephyr/dts/arm/st/f0/stm32f030X8.dtsi:10 */
	};

	/* node '/clocks' defined in zephyr/dts/arm/st/f0/stm32f0.dtsi:43 */
	clocks {

		/* node '/clocks/clk-hse' defined in zephyr/dts/arm/st/f0/stm32f0.dtsi:44 */
		clk_hse: clk-hse {
			#clock-cells = < 0x0 >;            /* in zephyr/dts/arm/st/f0/stm32f0.dtsi:45 */
			compatible = "st,stm32-hse-clock"; /* in zephyr/dts/arm/st/f0/stm32f0.dtsi:46 */
			status = "disabled";               /* in zephyr/dts/arm/st/f0/stm32f0.dtsi:47 */
		};

		/* node '/clocks/clk-hsi' defined in zephyr/dts/arm/st/f0/stm32f0.dtsi:50 */
		clk_hsi: clk-hsi {
			#clock-cells = < 0x0 >;         /* in zephyr/dts/arm/st/f0/stm32f0.dtsi:51 */
			compatible = "fixed-clock";     /* in zephyr/dts/arm/st/f0/stm32f0.dtsi:52 */
			clock-frequency = < 0x7a1200 >; /* in zephyr/dts/arm/st/f0/stm32f0.dtsi:53 */
			status = "disabled";            /* in zephyr/dts/arm/st/f0/stm32f0.dtsi:54 */
			phandle = < 0xe >;              /* in Outlaw-GPS-Tracker-Firmware/boards/deputy/deputy.dts:44 */
		};

		/* node '/clocks/clk-hsi14' defined in zephyr/dts/arm/st/f0/stm32f0.dtsi:57 */
		clk_hsi14: clk-hsi14 {
			#clock-cells = < 0x0 >;         /* in zephyr/dts/arm/st/f0/stm32f0.dtsi:58 */
			compatible = "fixed-clock";     /* in zephyr/dts/arm/st/f0/stm32f0.dtsi:59 */
			clock-frequency = < 0xd59f80 >; /* in zephyr/dts/arm/st/f0/stm32f0.dtsi:60 */
			status = "disabled";            /* in zephyr/dts/arm/st/f0/stm32f0.dtsi:61 */
		};

		/* node '/clocks/clk-lse' defined in zephyr/dts/arm/st/f0/stm32f0.dtsi:64 */
		clk_lse: clk-lse {
			#clock-cells = < 0x0 >;            /* in zephyr/dts/arm/st/f0/stm32f0.dtsi:65 */
			compatible = "st,stm32-lse-clock"; /* in zephyr/dts/arm/st/f0/stm32f0.dtsi:66 */
			clock-frequency = < 0x8000 >;      /* in zephyr/dts/arm/st/f0/stm32f0.dtsi:67 */
			driving-capability = < 0x0 >;      /* in zephyr/dts/arm/st/f0/stm32f0.dtsi:68 */
			status = "disabled";               /* in zephyr/dts/arm/st/f0/stm32f0.dtsi:69 */
		};

		/* node '/clocks/clk-lsi' defined in zephyr/dts/arm/st/f0/stm32f0.dtsi:72 */
		clk_lsi: clk-lsi {
			#clock-cells = < 0x0 >;       /* in zephyr/dts/arm/st/f0/stm32f0.dtsi:73 */
			compatible = "fixed-clock";   /* in zephyr/dts/arm/st/f0/stm32f0.dtsi:74 */
			clock-frequency = < 0x9c40 >; /* in zephyr/dts/arm/st/f0/stm32f0.dtsi:75 */
			status = "disabled";          /* in zephyr/dts/arm/st/f0/stm32f0.dtsi:76 */
		};

		/* node '/clocks/pll' defined in zephyr/dts/arm/st/f0/stm32f0.dtsi:79 */
		pll: pll {
			#clock-cells = < 0x0 >;              /* in zephyr/dts/arm/st/f0/stm32f0.dtsi:80 */
			compatible = "st,stm32f0-pll-clock"; /* in zephyr/dts/arm/st/f0/stm32f0.dtsi:81 */
			prediv = < 0x2 >;                    /* in Outlaw-GPS-Tracker-Firmware/boards/deputy/deputy.dts:42 */
			mul = < 0xc >;                       /* in Outlaw-GPS-Tracker-Firmware/boards/deputy/deputy.dts:43 */
			clocks = < &clk_hsi >;               /* in Outlaw-GPS-Tracker-Firmware/boards/deputy/deputy.dts:44 */
			status = "okay";                     /* in Outlaw-GPS-Tracker-Firmware/boards/deputy/deputy.dts:45 */
			phandle = < 0x3 >;                   /* in Outlaw-GPS-Tracker-Firmware/boards/deputy/deputy.dts:49 */
		};
	};

	/* node '/vref' defined in zephyr/dts/arm/st/f0/stm32f0.dtsi:381 */
	vref: vref {
		compatible = "st,stm32-vref";      /* in zephyr/dts/arm/st/f0/stm32f0.dtsi:382 */
		vrefint-cal-addr = < 0x1ffff7ba >; /* in zephyr/dts/arm/st/f0/stm32f0.dtsi:383 */
		vrefint-cal-mv = < 0xce4 >;        /* in zephyr/dts/arm/st/f0/stm32f0.dtsi:384 */
		io-channels = < &adc1 0x11 >;      /* in zephyr/dts/arm/st/f0/stm32f0.dtsi:385 */
		status = "disabled";               /* in zephyr/dts/arm/st/f0/stm32f0.dtsi:386 */
	};

	/* node '/smbus1' defined in zephyr/dts/arm/st/f0/stm32f0.dtsi:389 */
	smbus1: smbus1 {
		compatible = "st,stm32-smbus"; /* in zephyr/dts/arm/st/f0/stm32f0.dtsi:390 */
		#address-cells = < 0x1 >;      /* in zephyr/dts/arm/st/f0/stm32f0.dtsi:391 */
		#size-cells = < 0x0 >;         /* in zephyr/dts/arm/st/f0/stm32f0.dtsi:392 */
		i2c = < &i2c1 >;               /* in zephyr/dts/arm/st/f0/stm32f0.dtsi:393 */
		status = "disabled";           /* in zephyr/dts/arm/st/f0/stm32f0.dtsi:394 */
	};

	/* node '/dietemp' defined in zephyr/dts/arm/st/f0/stm32f030.dtsi:14 */
	die_temp: dietemp {
		compatible = "st,stm32c0-temp-cal"; /* in zephyr/dts/arm/st/f0/stm32f030.dtsi:15 */
		ts-cal1-addr = < 0x1ffff7b8 >;      /* in zephyr/dts/arm/st/f0/stm32f030.dtsi:16 */
		ts-cal1-temp = < 0x1e >;            /* in zephyr/dts/arm/st/f0/stm32f030.dtsi:17 */
		ts-cal-vrefanalog = < 0xce4 >;      /* in zephyr/dts/arm/st/f0/stm32f030.dtsi:18 */
		avgslope = "4.3";                   /* in zephyr/dts/arm/st/f0/stm32f030.dtsi:19 */
		io-channels = < &adc1 0x10 >;       /* in zephyr/dts/arm/st/f0/stm32f030.dtsi:20 */
		ntc;                                /* in zephyr/dts/arm/st/f0/stm32f030.dtsi:21 */
		status = "okay";                    /* in Outlaw-GPS-Tracker-Firmware/boards/deputy/deputy.dts:95 */
	};

	/* node '/smbus2' defined in zephyr/dts/arm/st/f0/stm32f030X8.dtsi:93 */
	smbus2: smbus2 {
		compatible = "st,stm32-smbus"; /* in zephyr/dts/arm/st/f0/stm32f030X8.dtsi:94 */
		#address-cells = < 0x1 >;      /* in zephyr/dts/arm/st/f0/stm32f030X8.dtsi:95 */
		#size-cells = < 0x0 >;         /* in zephyr/dts/arm/st/f0/stm32f030X8.dtsi:96 */
		i2c = < &i2c2 >;               /* in zephyr/dts/arm/st/f0/stm32f030X8.dtsi:97 */
		status = "disabled";           /* in zephyr/dts/arm/st/f0/stm32f030X8.dtsi:98 */
	};

	/* node '/leds' defined in Outlaw-GPS-Tracker-Firmware/boards/deputy/deputy.dts:23 */
	leds: leds {
		compatible = "gpio-leds"; /* in Outlaw-GPS-Tracker-Firmware/boards/deputy/deputy.dts:24 */

		/* node '/leds/led' defined in Outlaw-GPS-Tracker-Firmware/boards/deputy/deputy.dts:25 */
		led: led {
			gpios = < &gpiob 0xc 0x0 >; /* in Outlaw-GPS-Tracker-Firmware/boards/deputy/deputy.dts:26 */
			label = "User LD2";         /* in Outlaw-GPS-Tracker-Firmware/boards/deputy/deputy.dts:27 */
		};
	};
};
